# STM32G431C6T6 register map
File version: 1.0
Registers are 32-bit, access not given, reset 0x0 unless marked. A register's access mark holds for its fields unless they carry their own. Offsets are from the block's base; [hi:lo] are bit positions; {n}, {i} and the like mark numbered series; 'fields as' and 'values as' point back to an identical list.

## TIM6
Base 0x40001000
Same registers: TIM7 0x40001400, TIM1 0x40012C00, TIM8 0x40013400, TIM20 0x40015000
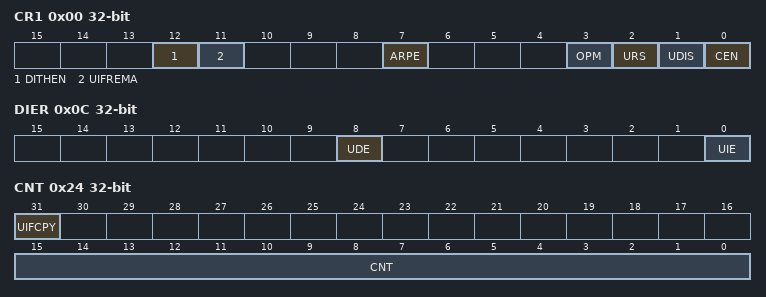
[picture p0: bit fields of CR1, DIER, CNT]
0x00 CR1
  [12] DITHEN, [11] UIFREMA, [7] ARPE, [3] OPM, [2] URS, [1] UDIS, [0] CEN
0x04 CR2
  [6:4] MMS
0x0C DIER
  [8] UDE, [0] UIE
0x10 SR
  [0] UIF
0x14 EGR
  [0] UG
0x24 CNT
  [31] UIFCPY, [15:0] CNT
0x28 PSC
  [15:0] PSC
0x2C ARR
  [19:0] ARR

## CRS
Base 0x40002000
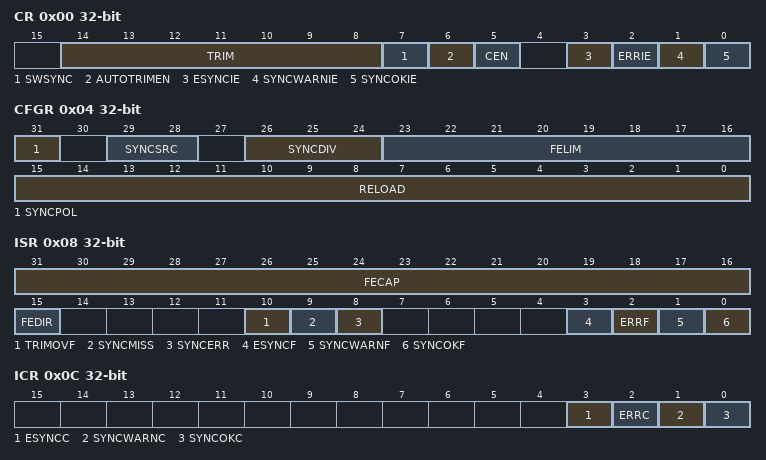
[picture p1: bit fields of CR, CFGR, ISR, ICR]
0x00 CR
  [14:8] TRIM, [7] SWSYNC, [6] AUTOTRIMEN, [5] CEN, [3] ESYNCIE, [2] ERRIE, [1] SYNCWARNIE, [0] SYNCOKIE
0x04 CFGR
  [31] SYNCPOL, [29:28] SYNCSRC, [26:24] SYNCDIV, [23:16] FELIM, [15:0] RELOAD
0x08 ISR
  [31:16] FECAP, [15] FEDIR, [10] TRIMOVF, [9] SYNCMISS, [8] SYNCERR, [3] ESYNCF, [2] ERRF, [1] SYNCWARNF, [0] SYNCOKF
0x0C ICR
  [3] ESYNCC, [2] ERRC, [1] SYNCWARNC, [0] SYNCOKC

## TAMP
Base 0x40002400
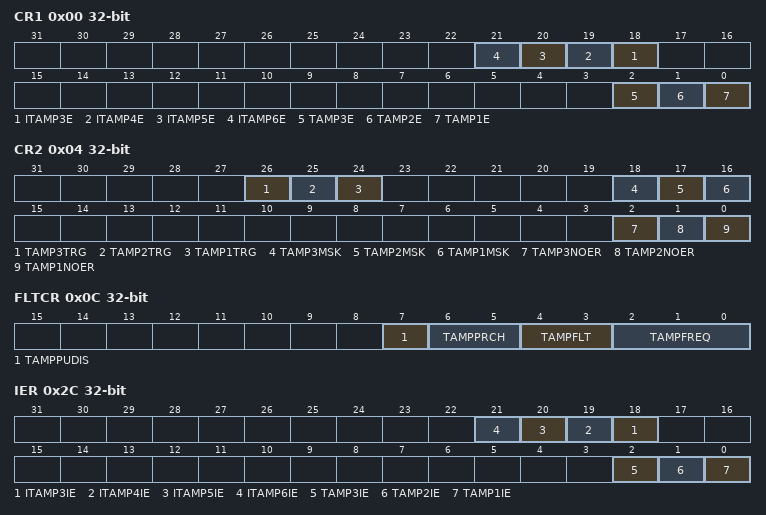
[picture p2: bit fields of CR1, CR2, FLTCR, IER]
0x00 CR1
  [n+15] ITAMP{n}E (n=3..6), [2] TAMP3E, [1] TAMP2E, [0] TAMP1E
0x04 CR2
  [26] TAMP3TRG, [25] TAMP2TRG, [24] TAMP1TRG, [18] TAMP3MSK, [17] TAMP2MSK, [16] TAMP1MSK, [2] TAMP3NOER, [1] TAMP2NOER, [0] TAMP1NOER
0x0C FLTCR
  [7] TAMPPUDIS, [6:5] TAMPPRCH, [4:3] TAMPFLT, [2:0] TAMPFREQ
0x2C IER
  [n+15] ITAMP{n}IE (n=3..6), [2] TAMP3IE, [1] TAMP2IE, [0] TAMP1IE
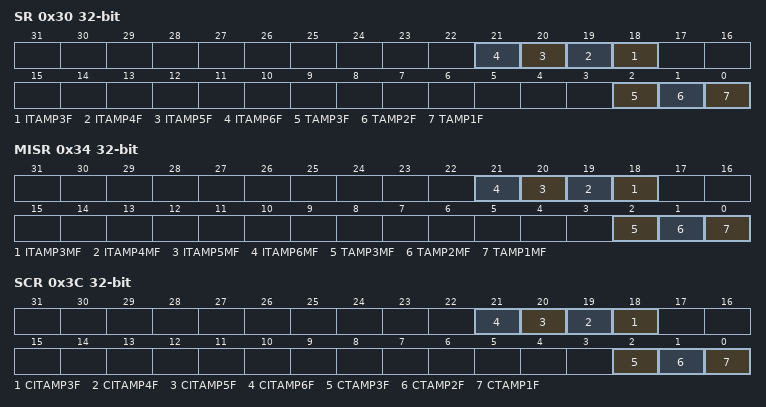
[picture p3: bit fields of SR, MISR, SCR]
0x30 SR
  [n+15] ITAMP{n}F (n=3..6), [2] TAMP3F, [1] TAMP2F, [0] TAMP1F
0x34 MISR
  [n+15] ITAMP{n}MF (n=3..6), [2] TAMP3MF, [1] TAMP2MF, [0] TAMP1MF
0x3C SCR
  [n+15] CITAMP{n}F (n=3..6), [2] CTAMP3F, [1] CTAMP2F, [0] CTAMP1F
{0x100+4i} BKP{i}R (i=0..31)
  [31:0] BKP

## BKP
Base 0x40002800
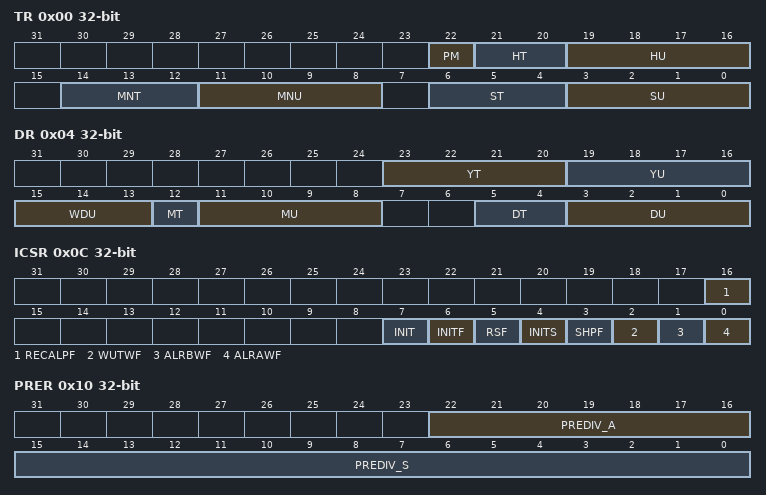
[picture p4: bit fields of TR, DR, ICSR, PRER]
0x00 TR
  [22] PM, [21:20] HT, [19:16] HU, [14:12] MNT, [11:8] MNU, [6:4] ST, [3:0] SU
0x04 DR
  [23:20] YT, [19:16] YU, [15:13] WDU, [12] MT, [11:8] MU, [5:4] DT, [3:0] DU
0x08 SSR
  [15:0] SS
0x0C ICSR
  [16] RECALPF, [7] INIT, [6] INITF, [5] RSF, [4] INITS, [3] SHPF, [2] WUTWF, [1] ALRBWF, [0] ALRAWF
0x10 PRER
  [22:16] PREDIV_A, [15:0] PREDIV_S
0x14 WUTR
  [15:0] WUT
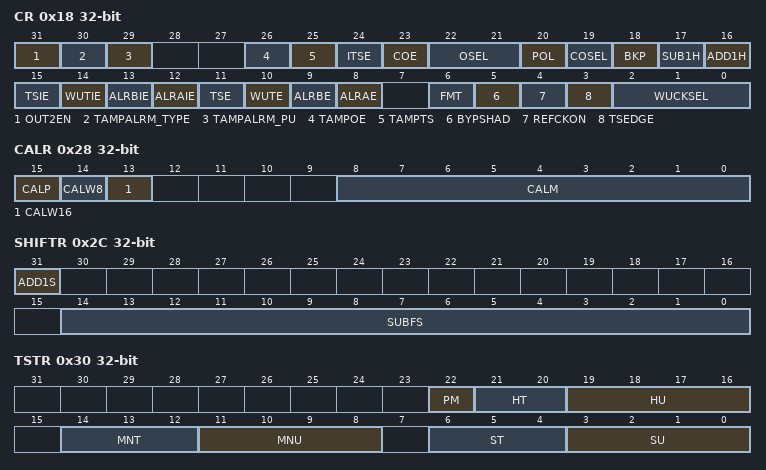
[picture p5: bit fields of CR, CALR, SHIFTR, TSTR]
0x18 CR
  [31] OUT2EN, [30] TAMPALRM_TYPE, [29] TAMPALRM_PU, [26] TAMPOE, [25] TAMPTS, [24] ITSE, [23] COE, [22:21] OSEL, [20] POL, [19] COSEL, [18] BKP, [17] SUB1H, [16] ADD1H, [15] TSIE, [14] WUTIE, [13] ALRBIE, [12] ALRAIE, [11] TSE, [10] WUTE, [9] ALRBE, [8] ALRAE, [6] FMT, [5] BYPSHAD, [4] REFCKON, [3] TSEDGE, [2:0] WUCKSEL
0x24 WPR
  [7:0] KEY
0x28 CALR
  [15] CALP, [14] CALW8, [13] CALW16, [8:0] CALM
0x2C SHIFTR
  [31] ADD1S, [14:0] SUBFS
0x30 TSTR
  fields as TR
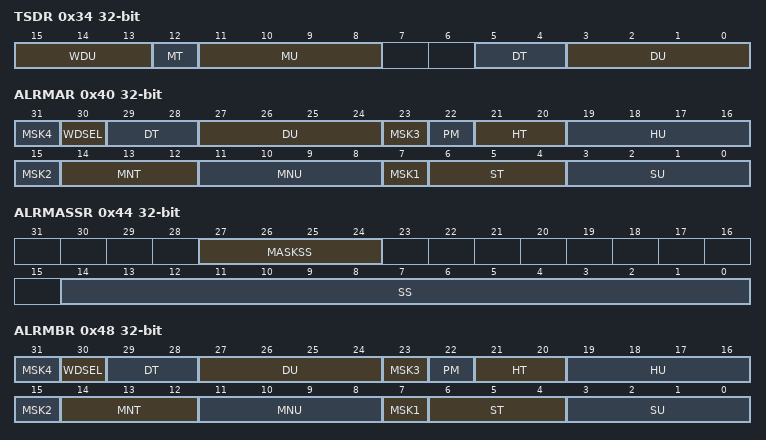
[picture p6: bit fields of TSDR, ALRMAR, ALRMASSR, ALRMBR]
0x34 TSDR
  [15:13] WDU, [12] MT, [11:8] MU, [5:4] DT, [3:0] DU
0x38 TSSSR
  [15:0] SS
0x40 ALRMAR
  [8n-1] MSK{n} (n=1..4), [30] WDSEL, [29:28] DT, [27:24] DU, [22] PM, [21:20] HT, [19:16] HU, [14:12] MNT, [11:8] MNU, [6:4] ST, [3:0] SU
0x44 ALRMASSR
  [27:24] MASKSS, [14:0] SS
0x48 ALRMBR
  fields as ALRMAR
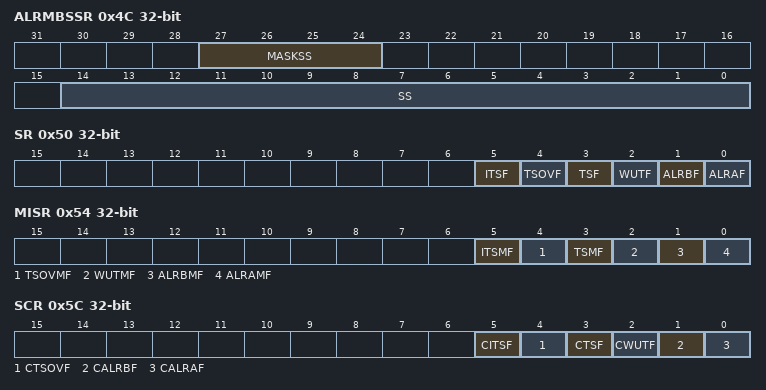
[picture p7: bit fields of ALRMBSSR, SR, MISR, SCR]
0x4C ALRMBSSR
  [27:24] MASKSS, [14:0] SS
0x50 SR
  [5] ITSF, [4] TSOVF, [3] TSF, [2] WUTF, [1] ALRBF, [0] ALRAF
0x54 MISR
  [5] ITSMF, [4] TSOVMF, [3] TSMF, [2] WUTMF, [1] ALRBMF, [0] ALRAMF
0x5C SCR
  [5] CITSF, [4] CTSOVF, [3] CTSF, [2] CWUTF, [1] CALRBF, [0] CALRAF

## RTC
Base 0x40002800
Registers as BKP; these are added or differ:
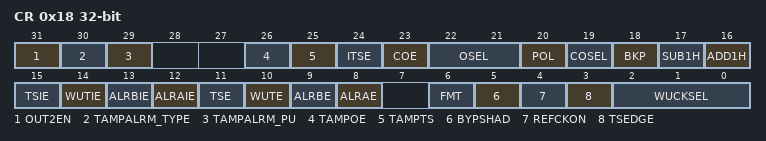
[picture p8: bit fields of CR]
0x18 CR
  fields as BKP.CR

## WWDG
Base 0x40002C00
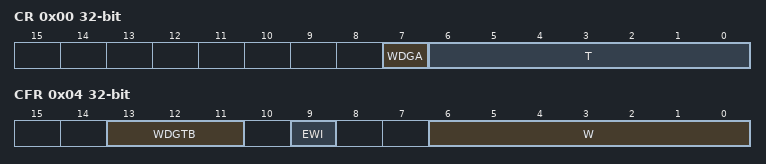
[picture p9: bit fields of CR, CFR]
0x00 CR
  [7] WDGA, [6:0] T
0x04 CFR
  [13:11] WDGTB, [9] EWI, [6:0] W
0x08 SR
  [0] EWIF

## IWDG
Base 0x40003000
0x00 KR
  [15:0] KEY
0x04 PR
  [2:0] PR
0x08 RLR
  [11:0] RL
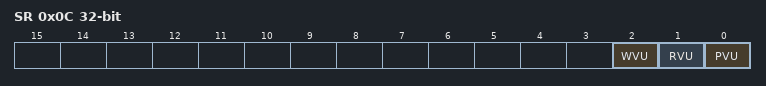
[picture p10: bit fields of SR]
0x0C SR
  [2] WVU, [1] RVU, [0] PVU
0x10 WINR
  [11:0] WIN

## SPI2
Base 0x40003800
Same registers: SPI3 0x40003C00, SPI1 0x40013000, SPI4 0x40013C00
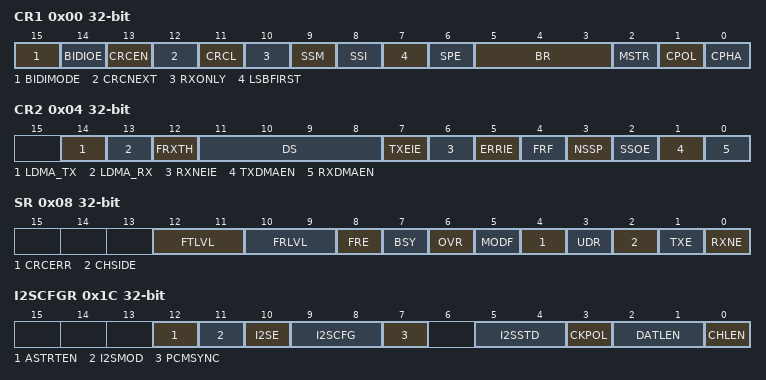
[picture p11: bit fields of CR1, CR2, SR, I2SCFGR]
0x00 CR1
  [15] BIDIMODE, [14] BIDIOE, [13] CRCEN, [12] CRCNEXT, [11] CRCL, [10] RXONLY, [9] SSM, [8] SSI, [7] LSBFIRST, [6] SPE, [5:3] BR, [2] MSTR, [1] CPOL, [0] CPHA
0x04 CR2
  [14] LDMA_TX, [13] LDMA_RX, [12] FRXTH, [11:8] DS, [7] TXEIE, [6] RXNEIE, [5] ERRIE, [4] FRF, [3] NSSP, [2] SSOE, [1] TXDMAEN, [0] RXDMAEN
0x08 SR
  [12:11] FTLVL, [10:9] FRLVL, [8] FRE, [7] BSY, [6] OVR, [5] MODF, [4] CRCERR, [3] UDR, [2] CHSIDE, [1] TXE, [0] RXNE
0x0C DR
  [15:0] DR
0x10 CRCPR
  [15:0] CRCPOLY
0x14 RXCRCR
  [15:0] RXCRC
0x18 TXCRCR
  [15:0] TXCRC
0x1C I2SCFGR
  [12] ASTRTEN, [11] I2SMOD, [10] I2SE, [9:8] I2SCFG, [7] PCMSYNC, [5:4] I2SSTD, [3] CKPOL, [2:1] DATLEN, [0] CHLEN
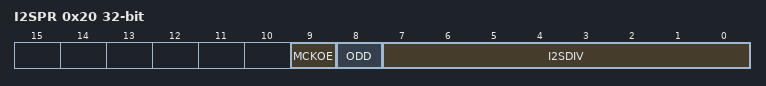
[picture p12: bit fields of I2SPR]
0x20 I2SPR
  [9] MCKOE, [8] ODD, [7:0] I2SDIV
